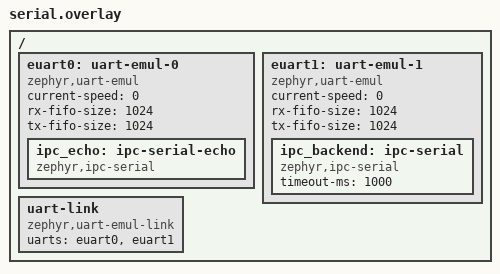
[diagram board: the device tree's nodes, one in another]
/*
 * SPDX-License-Identifier: Apache-2.0
 */

/ {
	euart0: uart-emul-0 {
		compatible = "zephyr,uart-emul";
		status = "okay";
		current-speed = <0>;
		rx-fifo-size = <1024>;
		tx-fifo-size = <1024>;

		ipc_echo: ipc-serial-echo {
			compatible = "zephyr,ipc-serial";
			status = "okay";
		};
	};

	euart1: uart-emul-1 {
		compatible = "zephyr,uart-emul";
		status = "okay";
		current-speed = <0>;
		rx-fifo-size = <1024>;
		tx-fifo-size = <1024>;

		ipc_backend: ipc-serial {
			compatible = "zephyr,ipc-serial";
			status = "okay";
			timeout-ms = <1000>;
		};
	};

	uart-link {
		compatible = "zephyr,uart-emul-link";
		status = "okay";

		uarts = <&euart0 &euart1>;
	};
};
